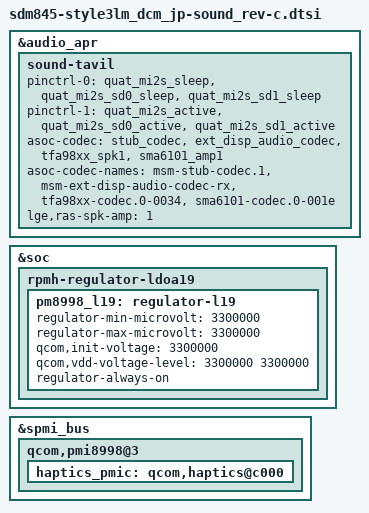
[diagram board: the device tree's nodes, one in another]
/* Copyright (c) 2017, The Linux Foundation. All rights reserved.
 *
 * This program is free software; you can redistribute it and/or modify
 * it under the terms of the GNU General Public License version 2 and
 * only version 2 as published by the Free Software Foundation.
 *
 * This program is distributed in the hope that it will be useful,
 * but WITHOUT ANY WARRANTY; without even the implied warranty of
 * MERCHANTABILITY or FITNESS FOR A PARTICULAR PURPOSE.  See the
 * GNU General Public License for more details.
 */

#include "../sdm845-style3lm_common/sdm845-style3lm_common-sound.dtsi"
#include "../sdm845-style3lm_common/sdm845-style3lm_common-sound-tfa9872.dtsi"
#include "../sdm845-style3lm_common/sdm845-style3lm_common-sound-sma6101.dtsi"
#include "../sdm845-style3lm_common/sdm845-style3lm_common-sound-vibrator.dtsi"

&audio_apr {
	sound-tavil {
		pinctrl-names = "quat-mi2s-sleep", "quat-mi2s-active";
		pinctrl-0 = <&quat_mi2s_sleep &quat_mi2s_sd0_sleep &quat_mi2s_sd1_sleep>;
		pinctrl-1 = <&quat_mi2s_active &quat_mi2s_sd0_active &quat_mi2s_sd1_active>;
		asoc-codec = <&stub_codec>,  <&ext_disp_audio_codec>, <&tfa98xx_spk1>, <&sma6101_amp1>;
		asoc-codec-names = "msm-stub-codec.1",
				"msm-ext-disp-audio-codec-rx",
				"tfa98xx-codec.0-0034",
				"sma6101-codec.0-001e";
	};
};

&soc {
	rpmh-regulator-ldoa19 {
		status = "ok";
		pm8998_l19: regulator-l19 {
				regulator-min-microvolt = <3300000>;
				regulator-max-microvolt = <3300000>;
				qcom,init-voltage = <3300000>;
				qcom,vdd-voltage-level = <3300000 3300000>;
				regulator-always-on;
				status = "okay";
			};
	};
	
};

&audio_apr {
	sound-tavil {
		/* to register multi codec dai for sma6101 and tfa9872 */
		lge,ras-spk-amp = <1>;
	};
};

&spmi_bus {
	qcom,pmi8998@3 {
		haptics_pmic: qcom,haptics@c000 {
			status = "okay";
		};
	};
};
